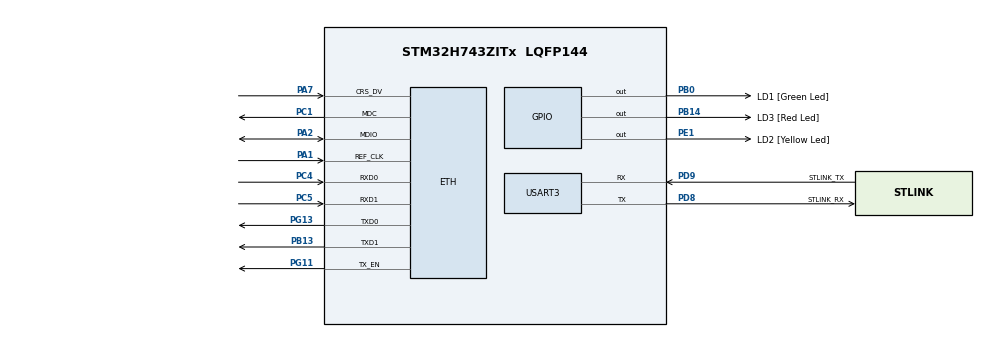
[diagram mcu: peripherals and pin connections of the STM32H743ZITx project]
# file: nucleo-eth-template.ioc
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CORTEX_M7.AccessPermission-Cortex_Memory_Protection_Unit_Region0_Settings=MPU_REGION_FULL_ACCESS
CORTEX_M7.AccessPermission-Cortex_Memory_Protection_Unit_Region1_Settings=MPU_REGION_FULL_ACCESS
CORTEX_M7.BaseAddress-Cortex_Memory_Protection_Unit_Region0_Settings=0x30040000
CORTEX_M7.BaseAddress-Cortex_Memory_Protection_Unit_Region1_Settings=0x30044000
CORTEX_M7.CPU_DCache=Enabled
CORTEX_M7.CPU_ICache=Enabled
CORTEX_M7.Enable-Cortex_Memory_Protection_Unit_Region0_Settings=MPU_REGION_ENABLE
CORTEX_M7.Enable-Cortex_Memory_Protection_Unit_Region1_Settings=MPU_REGION_ENABLE
CORTEX_M7.IsBufferable-Cortex_Memory_Protection_Unit_Region0_Settings=MPU_ACCESS_BUFFERABLE
CORTEX_M7.IsShareable-Cortex_Memory_Protection_Unit_Region1_Settings=MPU_ACCESS_SHAREABLE
CORTEX_M7.MPU_Control=MPU_PRIVILEGED_DEFAULT
CORTEX_M7.Size-Cortex_Memory_Protection_Unit_Region0_Settings=MPU_REGION_SIZE_256B
CORTEX_M7.Size-Cortex_Memory_Protection_Unit_Region1_Settings=MPU_REGION_SIZE_16KB
CORTEX_M7.TypeExtField-Cortex_Memory_Protection_Unit_Region1_Settings=MPU_TEX_LEVEL1
ETH.MACAddr=02\:00\:00\:00\:00\:01
ETH.MediaInterface=HAL_ETH_RMII_MODE
ETH.RxBuffAddress=0x30040200
LWIP.BSP.number=1
LWIP.GATEWAY_ADDRESS=000.000.000.000
LWIP.IP_ADDRESS=192.168.003.111
LWIP.LWIP_DHCP=0
LWIP.NETMASK_ADDRESS=255.255.255.000
LWIP.Version=v2.1.2_Cube
LWIP0.BSP.STBoard=false
LWIP0.BSP.api=BSP_COMPONENT_DRIVER
LWIP0.BSP.component=LAN8742
LWIP0.BSP.instance=LAN8742
LWIP0.BSP.name=Driver_PHY
LWIP0.BSP.solution=LAN8742
Mcu.Family=STM32H7
Mcu.Name=STM32H743ZITx
Mcu.Package=LQFP144
NVIC.ETH_IRQn=true\:5\:0\:true\:false\:true\:true\:true\:true
NVIC.PriorityGroup=NVIC_PRIORITYGROUP_4
NVIC.TIM6_DAC_IRQn=true\:15\:0\:false\:false\:true\:false\:true\:true
NVIC.TIM7_IRQn=true\:0\:0\:false\:false\:true\:true\:true\:true
NVIC.TimeBase=TIM6_DAC_IRQn
NVIC.TimeBaseIP=TIM6
PA1.GPIO_Speed=GPIO_SPEED_FREQ_HIGH
PA1.Mode=RMII
PA1.Signal=ETH_REF_CLK
PA2.GPIO_Speed=GPIO_SPEED_FREQ_HIGH
PA2.Mode=RMII
PA2.Signal=ETH_MDIO
PA7.GPIO_Speed=GPIO_SPEED_FREQ_HIGH
PA7.Mode=RMII
PA7.Signal=ETH_CRS_DV
PB0.GPIO_Label=LD1 [Green Led]
PB0.GPIO_Speed=GPIO_SPEED_FREQ_VERY_HIGH
PB0.Signal=GPIO_Output
PB13.GPIO_Speed=GPIO_SPEED_FREQ_HIGH
PB13.Mode=RMII
PB13.Signal=ETH_TXD1
PB14.GPIO_Label=LD3 [Red Led]
PB14.GPIO_Speed=GPIO_SPEED_FREQ_VERY_HIGH
PB14.Signal=GPIO_Output
PC1.GPIO_Speed=GPIO_SPEED_FREQ_HIGH
PC1.Mode=RMII
PC1.Signal=ETH_MDC
PC14-OSC32_IN\ (OSC32_IN).Mode=LSE-External-Clock-Source
PC14-OSC32_IN\ (OSC32_IN).Signal=RCC_OSC32_IN
PC4.GPIO_Speed=GPIO_SPEED_FREQ_HIGH
PC4.Mode=RMII
PC4.Signal=ETH_RXD0
PC5.GPIO_Speed=GPIO_SPEED_FREQ_HIGH
PC5.Mode=RMII
PC5.Signal=ETH_RXD1
PD8.GPIO_Label=STLINK_RX
PD8.GPIO_Speed=GPIO_SPEED_FREQ_HIGH
PD8.Mode=Asynchronous
PD8.Signal=USART3_TX
PD9.GPIO_Label=STLINK_TX
PD9.GPIO_Speed=GPIO_SPEED_FREQ_HIGH
PD9.Mode=Asynchronous
PD9.Signal=USART3_RX
PE1.GPIO_Label=LD2 [Yellow Led]
PE1.GPIO_Speed=GPIO_SPEED_FREQ_VERY_HIGH
PE1.Signal=GPIO_Output
PG11.GPIO_Speed=GPIO_SPEED_FREQ_HIGH
PG11.Mode=RMII
PG11.Signal=ETH_TX_EN
PG13.GPIO_Speed=GPIO_SPEED_FREQ_HIGH
PG13.Mode=RMII
PG13.Signal=ETH_TXD0
PH0-OSC_IN\ (PH0).Signal=RCC_OSC_IN
ProjectManager.HeapSize=0x200
ProjectManager.StackSize=0x400
ProjectManager.TargetToolchain=STM32CubeIDE
RCC.ADCFreq_Value=150000000
RCC.APB1Freq_Value=40000000
RCC.APB2Freq_Value=40000000
RCC.APB3Freq_Value=80000000
RCC.APB4Freq_Value=80000000
RCC.CortexFreq_Value=80000000
RCC.D2PPRE1=RCC_APB1_DIV2
RCC.D2PPRE2=RCC_APB2_DIV2
RCC.DIVM1=4
RCC.DIVM2=4
RCC.DIVN1=10
RCC.DIVN2=9
RCC.DIVP2=1
RCC.HCLKFreq_Value=80000000
RCC.HSE_VALUE=8000000
RCC.PLL2FRACN=3072
RCC.PLL3FRACN=0
RCC.PLLFRACN=0
RCC.SYSCLKFreq_VALUE=80000000
RCC.SYSCLKSource=RCC_SYSCLKSOURCE_PLLCLK
RCC.USBFreq_Value=80000000
TIM7.Period=300
TIM7.Prescaler=80
USART3.VirtualMode-Asynchronous=VM_ASYNC
VP_LWIP_VS_Enabled.Mode=Enabled
VP_SYS_VS_tim6.Mode=TIM6
VP_TIM7_VS_ClockSourceINT.Mode=Enable_Timer
board=NUCLEO-H743ZI2

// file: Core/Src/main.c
/* USER CODE BEGIN Header */
/**
  ******************************************************************************
  * @file           : main.c
  * @brief          : Main program body
  ******************************************************************************
  * @attention
  *
  * Copyright (c) 2022 STMicroelectronics.
  * All rights reserved.
  *
  * This software is licensed under terms that can be found in the LICENSE file
  * in the root directory of this software component.
  * If no LICENSE file comes with this software, it is provided AS-IS.
  *
  ******************************************************************************
  */
/* USER CODE END Header */
#include "main.h"
#include "lwip.h"

/* USER CODE BEGIN Includes */
//#include "lwip/sockets.h"          <----
//#include <string.h>
#include "tcpServerRAW.h"
//#include "tcpClientRAW.h"
#include "interface.h"
//#include <stdio.h>
//#include <stdlib.h>
/* USER CODE END Includes */

/* USER CODE BEGIN PD */
//#define PORT	5015          <----
/* USER CODE END PD */

TIM_HandleTypeDef htim7;

UART_HandleTypeDef huart3;

void SystemClock_Config(void);
static void MPU_Config(void);
static void MX_GPIO_Init(void);
static void MX_USART3_UART_Init(void);
static void MX_TIM7_Init(void);

/* USER CODE BEGIN 0 */

extern struct netif gnetif;
extern parameters par;
int32_t raw;
/* USER CODE END 0 */

int main(void)
{

  /* MPU Configuration--------------------------------------------------------*/
  MPU_Config();

  /* Enable I-Cache---------------------------------------------------------*/
  SCB_EnableICache();

  /* Enable D-Cache---------------------------------------------------------*/
  SCB_EnableDCache();

  /* MCU Configuration--------------------------------------------------------*/

  /* Reset of all peripherals, Initializes the Flash interface and the Systick. */
  HAL_Init();

  /* Configure the system clock */
  SystemClock_Config();

  /* Initialize all configured peripherals */
  MX_GPIO_Init();
  MX_USART3_UART_Init();
  MX_LWIP_Init();
  MX_TIM7_Init();
  /* USER CODE BEGIN 2 */

  tcp_server_init();
  //tcp_client_init();
  tcp_server_init();
  initInterface();

  HAL_TIM_Base_Start_IT(&htim7);

  /* USER CODE END 2 */

  /* Infinite loop */
  while (1)
  {

    /* USER CODE BEGIN 3 */
	  ethernetif_input(&gnetif);
	  sys_check_timeouts();

	}
  /* USER CODE END 3 */
}

void SystemClock_Config(void)
{
  RCC_OscInitTypeDef RCC_OscInitStruct = {0};
  RCC_ClkInitTypeDef RCC_ClkInitStruct = {0};

  /** Supply configuration update enable
  */
  HAL_PWREx_ConfigSupply(PWR_LDO_SUPPLY);
  /** Configure the main internal regulator output voltage
  */
  __HAL_PWR_VOLTAGESCALING_CONFIG(PWR_REGULATOR_VOLTAGE_SCALE3);

  while(!__HAL_PWR_GET_FLAG(PWR_FLAG_VOSRDY)) {}
  /** Initializes the RCC Oscillators according to the specified parameters
  * in the RCC_OscInitTypeDef structure.
  */
  RCC_OscInitStruct.OscillatorType = RCC_OSCILLATORTYPE_HSI;
  RCC_OscInitStruct.HSIState = RCC_HSI_DIV1;
  RCC_OscInitStruct.HSICalibrationValue = RCC_HSICALIBRATION_DEFAULT;
  RCC_OscInitStruct.PLL.PLLState = RCC_PLL_ON;
  RCC_OscInitStruct.PLL.PLLSource = RCC_PLLSOURCE_HSI;
  RCC_OscInitStruct.PLL.PLLM = 4;
  RCC_OscInitStruct.PLL.PLLN = 10;
  RCC_OscInitStruct.PLL.PLLP = 2;
  RCC_OscInitStruct.PLL.PLLQ = 2;
  RCC_OscInitStruct.PLL.PLLR = 2;
  RCC_OscInitStruct.PLL.PLLRGE = RCC_PLL1VCIRANGE_3;
  RCC_OscInitStruct.PLL.PLLVCOSEL = RCC_PLL1VCOMEDIUM;
  RCC_OscInitStruct.PLL.PLLFRACN = 0;
  if (HAL_RCC_OscConfig(&RCC_OscInitStruct) != HAL_OK)
  {
    Error_Handler();
  }
  /** Initializes the CPU, AHB and APB buses clocks
  */
  RCC_ClkInitStruct.ClockType = RCC_CLOCKTYPE_HCLK|RCC_CLOCKTYPE_SYSCLK
                              |RCC_CLOCKTYPE_PCLK1|RCC_CLOCKTYPE_PCLK2
                              |RCC_CLOCKTYPE_D3PCLK1|RCC_CLOCKTYPE_D1PCLK1;
  RCC_ClkInitStruct.SYSCLKSource = RCC_SYSCLKSOURCE_PLLCLK;
  RCC_ClkInitStruct.SYSCLKDivider = RCC_SYSCLK_DIV1;
  RCC_ClkInitStruct.AHBCLKDivider = RCC_HCLK_DIV1;
  RCC_ClkInitStruct.APB3CLKDivider = RCC_APB3_DIV1;
  RCC_ClkInitStruct.APB1CLKDivider = RCC_APB1_DIV2;
  RCC_ClkInitStruct.APB2CLKDivider = RCC_APB2_DIV2;
  RCC_ClkInitStruct.APB4CLKDivider = RCC_APB4_DIV1;

  if (HAL_RCC_ClockConfig(&RCC_ClkInitStruct, FLASH_LATENCY_1) != HAL_OK)
  {
    Error_Handler();
  }
}

static void MX_TIM7_Init(void)
{

  TIM_MasterConfigTypeDef sMasterConfig = {0};

  htim7.Instance = TIM7;
  htim7.Init.Prescaler = 80;
  htim7.Init.CounterMode = TIM_COUNTERMODE_UP;
  htim7.Init.Period = 300;
  htim7.Init.AutoReloadPreload = TIM_AUTORELOAD_PRELOAD_DISABLE;
  if (HAL_TIM_Base_Init(&htim7) != HAL_OK)
  {
    Error_Handler();
  }
  sMasterConfig.MasterOutputTrigger = TIM_TRGO_RESET;
  sMasterConfig.MasterSlaveMode = TIM_MASTERSLAVEMODE_DISABLE;
  if (HAL_TIMEx_MasterConfigSynchronization(&htim7, &sMasterConfig) != HAL_OK)
  {
    Error_Handler();
  }

}

static void MX_USART3_UART_Init(void)
{

  huart3.Instance = USART3;
  huart3.Init.BaudRate = 115200;
  huart3.Init.WordLength = UART_WORDLENGTH_8B;
  huart3.Init.StopBits = UART_STOPBITS_1;
  huart3.Init.Parity = UART_PARITY_NONE;
  huart3.Init.Mode = UART_MODE_TX_RX;
  huart3.Init.HwFlowCtl = UART_HWCONTROL_NONE;
  huart3.Init.OverSampling = UART_OVERSAMPLING_16;
  huart3.Init.OneBitSampling = UART_ONE_BIT_SAMPLE_DISABLE;
  huart3.Init.ClockPrescaler = UART_PRESCALER_DIV1;
  huart3.AdvancedInit.AdvFeatureInit = UART_ADVFEATURE_NO_INIT;
  if (HAL_UART_Init(&huart3) != HAL_OK)
  {
    Error_Handler();
  }
  if (HAL_UARTEx_SetTxFifoThreshold(&huart3, UART_TXFIFO_THRESHOLD_1_8) != HAL_OK)
  {
    Error_Handler();
  }
  if (HAL_UARTEx_SetRxFifoThreshold(&huart3, UART_RXFIFO_THRESHOLD_1_8) != HAL_OK)
  {
    Error_Handler();
  }
  if (HAL_UARTEx_DisableFifoMode(&huart3) != HAL_OK)
  {
    Error_Handler();
  }

}

static void MX_GPIO_Init(void)
{
  GPIO_InitTypeDef GPIO_InitStruct = {0};

  /* GPIO Ports Clock Enable */
  __HAL_RCC_GPIOC_CLK_ENABLE();
  __HAL_RCC_GPIOH_CLK_ENABLE();
  __HAL_RCC_GPIOA_CLK_ENABLE();
  __HAL_RCC_GPIOB_CLK_ENABLE();
  __HAL_RCC_GPIOD_CLK_ENABLE();
  __HAL_RCC_GPIOG_CLK_ENABLE();
  __HAL_RCC_GPIOE_CLK_ENABLE();

  /*Configure GPIO pin Output Level */
  HAL_GPIO_WritePin(GPIOB, LD1_Pin|LD3_Pin, GPIO_PIN_RESET);

  /*Configure GPIO pin Output Level */
  HAL_GPIO_WritePin(LD2_GPIO_Port, LD2_Pin, GPIO_PIN_RESET);

  /*Configure GPIO pins : LD1_Pin LD3_Pin */
  GPIO_InitStruct.Pin = LD1_Pin|LD3_Pin;
  GPIO_InitStruct.Mode = GPIO_MODE_OUTPUT_PP;
  GPIO_InitStruct.Pull = GPIO_NOPULL;
  GPIO_InitStruct.Speed = GPIO_SPEED_FREQ_VERY_HIGH;
  HAL_GPIO_Init(GPIOB, &GPIO_InitStruct);

  /*Configure GPIO pin : LD2_Pin */
  GPIO_InitStruct.Pin = LD2_Pin;
  GPIO_InitStruct.Mode = GPIO_MODE_OUTPUT_PP;
  GPIO_InitStruct.Pull = GPIO_NOPULL;
  GPIO_InitStruct.Speed = GPIO_SPEED_FREQ_VERY_HIGH;
  HAL_GPIO_Init(LD2_GPIO_Port, &GPIO_InitStruct);

}

/* MPU Configuration */

void MPU_Config(void)
{
  MPU_Region_InitTypeDef MPU_InitStruct = {0};

  /* Disables the MPU */
  HAL_MPU_Disable();
  /** Initializes and configures the Region and the memory to be protected
  */
  MPU_InitStruct.Enable = MPU_REGION_ENABLE;
  MPU_InitStruct.Number = MPU_REGION_NUMBER0;
  MPU_InitStruct.BaseAddress = 0x30040000;
  MPU_InitStruct.Size = MPU_REGION_SIZE_256B;
  MPU_InitStruct.SubRegionDisable = 0x0;
  MPU_InitStruct.TypeExtField = MPU_TEX_LEVEL0;
  MPU_InitStruct.AccessPermission = MPU_REGION_FULL_ACCESS;
  MPU_InitStruct.DisableExec = MPU_INSTRUCTION_ACCESS_ENABLE;
  MPU_InitStruct.IsShareable = MPU_ACCESS_NOT_SHAREABLE;
  MPU_InitStruct.IsCacheable = MPU_ACCESS_NOT_CACHEABLE;
  MPU_InitStruct.IsBufferable = MPU_ACCESS_BUFFERABLE;

  HAL_MPU_ConfigRegion(&MPU_InitStruct);
  /** Initializes and configures the Region and the memory to be protected
  */
  MPU_InitStruct.Number = MPU_REGION_NUMBER1;
  MPU_InitStruct.BaseAddress = 0x30044000;
  MPU_InitStruct.Size = MPU_REGION_SIZE_16KB;
  MPU_InitStruct.TypeExtField = MPU_TEX_LEVEL1;
  MPU_InitStruct.IsShareable = MPU_ACCESS_SHAREABLE;
  MPU_InitStruct.IsBufferable = MPU_ACCESS_NOT_BUFFERABLE;

  HAL_MPU_ConfigRegion(&MPU_InitStruct);
  /* Enables the MPU */
  HAL_MPU_Enable(MPU_PRIVILEGED_DEFAULT);

}

void HAL_TIM_PeriodElapsedCallback(TIM_HandleTypeDef *htim)
{
  if (htim->Instance == TIM6) {
    HAL_IncTick();
  }
  /* USER CODE BEGIN Callback 1 */
  if (htim->Instance == TIM7) {
	  HAL_GPIO_WritePin(LD1_GPIO_Port, LD1_Pin, SET);

	  HAL_GPIO_WritePin(LD1_GPIO_Port, LD1_Pin, RESET);
    }
  /* USER CODE END Callback 1 */
}

void Error_Handler(void)
{
  __disable_irq();
  while (1)
  {
  }
}
